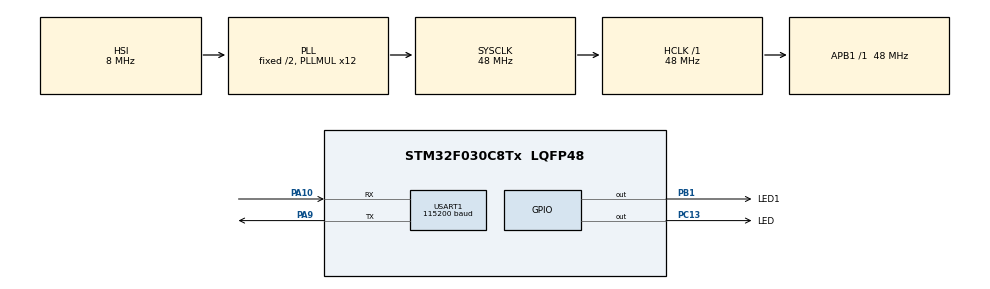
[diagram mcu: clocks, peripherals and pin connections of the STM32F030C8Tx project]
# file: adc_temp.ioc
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Mcu.Family=STM32F0
Mcu.Name=STM32F030C8Tx
Mcu.Package=LQFP48
NVIC.ADC1_IRQn=true\:0\:0\:false\:false\:true\:true\:true\:true
PA10.Mode=Asynchronous
PA10.Signal=USART1_RX
PA13.Mode=Serial_Wire
PA13.Signal=SYS_SWDIO
PA14.Mode=Serial_Wire
PA14.Signal=SYS_SWCLK
PA9.Mode=Asynchronous
PA9.Signal=USART1_TX
PB1.GPIO_Label=LED1
PB1.Signal=GPIO_Output
PC13.GPIO_Label=LED
PC13.PinState=GPIO_PIN_SET
PC13.Signal=GPIO_Output
PC14-OSC32_IN.Mode=LSE-External-Oscillator
PC14-OSC32_IN.Signal=RCC_OSC32_IN
PC15-OSC32_OUT.Mode=LSE-External-Oscillator
PC15-OSC32_OUT.Signal=RCC_OSC32_OUT
PF0-OSC_IN.Mode=HSE-External-Oscillator
PF0-OSC_IN.Signal=RCC_OSC_IN
PF1-OSC_OUT.Mode=HSE-External-Oscillator
PF1-OSC_OUT.Signal=RCC_OSC_OUT
ProjectManager.HeapSize=0x200
ProjectManager.StackSize=0x400
ProjectManager.TargetToolchain=MDK-ARM V5.32
RCC.AHBFreq_Value=48000000
RCC.APB1Freq_Value=48000000
RCC.APB1TimFreq_Value=48000000
RCC.HCLKFreq_Value=48000000
RCC.PLLMUL=RCC_PLL_MUL12
RCC.SYSCLKFreq_VALUE=48000000
RCC.SYSCLKSource=RCC_SYSCLKSOURCE_PLLCLK
USART1.BaudRate=115200
USART1.VirtualMode-Asynchronous=VM_ASYNC
VP_ADC_TempSens_Input.Mode=IN-TempSens
board=custom

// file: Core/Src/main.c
/* USER CODE BEGIN Header */
/**
  ******************************************************************************
  * @file           : main.c
  * @brief          : Main program body
  ******************************************************************************
  * @attention
  *
  * Copyright (c) 2023 STMicroelectronics.
  * All rights reserved.
  *
  * This software is licensed under terms that can be found in the LICENSE file
  * in the root directory of this software component.
  * If no LICENSE file comes with this software, it is provided AS-IS.
  *
  ******************************************************************************
  */
/* USER CODE END Header */
#include "main.h"
#include "adc.h"
#include "usart.h"
#include "gpio.h"

void SystemClock_Config(void);

int main(void)
{

  /* MCU Configuration--------------------------------------------------------*/

  /* Reset of all peripherals, Initializes the Flash interface and the Systick. */
  HAL_Init();

  /* Configure the system clock */
  SystemClock_Config();

  /* Initialize all configured peripherals */
  MX_GPIO_Init();
  MX_USART1_UART_Init();
  MX_ADC_Init();

  /* Infinite loop */
  /* USER CODE BEGIN WHILE */
  while (1)
  {
	  uint32_t v;
	float vt,temp;
	  v=0;vt=0;temp=0;
	  HAL_ADC_Start(&hadc);
	  v=HAL_ADC_GetValue(&hadc);
	  vt=v*3.3/4095;
	  temp=(1520-vt*1000)/4.6+30;
	  printf("vt=%f<----->temp=%f\r\n",vt,temp);
	  HAL_Delay(500);
    /* USER CODE END WHILE */

  }
}

void SystemClock_Config(void)
{
  RCC_OscInitTypeDef RCC_OscInitStruct = {0};
  RCC_ClkInitTypeDef RCC_ClkInitStruct = {0};
  RCC_PeriphCLKInitTypeDef PeriphClkInit = {0};

  /** Initializes the RCC Oscillators according to the specified parameters
  * in the RCC_OscInitTypeDef structure.
  */
  RCC_OscInitStruct.OscillatorType = RCC_OSCILLATORTYPE_HSI|RCC_OSCILLATORTYPE_HSI14;
  RCC_OscInitStruct.HSIState = RCC_HSI_ON;
  RCC_OscInitStruct.HSI14State = RCC_HSI14_ON;
  RCC_OscInitStruct.HSICalibrationValue = RCC_HSICALIBRATION_DEFAULT;
  RCC_OscInitStruct.HSI14CalibrationValue = 16;
  RCC_OscInitStruct.PLL.PLLState = RCC_PLL_ON;
  RCC_OscInitStruct.PLL.PLLSource = RCC_PLLSOURCE_HSI;
  RCC_OscInitStruct.PLL.PLLMUL = RCC_PLL_MUL12;
  RCC_OscInitStruct.PLL.PREDIV = RCC_PREDIV_DIV1;
  if (HAL_RCC_OscConfig(&RCC_OscInitStruct) != HAL_OK)
  {
    Error_Handler();
  }

  /** Initializes the CPU, AHB and APB buses clocks
  */
  RCC_ClkInitStruct.ClockType = RCC_CLOCKTYPE_HCLK|RCC_CLOCKTYPE_SYSCLK
                              |RCC_CLOCKTYPE_PCLK1;
  RCC_ClkInitStruct.SYSCLKSource = RCC_SYSCLKSOURCE_PLLCLK;
  RCC_ClkInitStruct.AHBCLKDivider = RCC_SYSCLK_DIV1;
  RCC_ClkInitStruct.APB1CLKDivider = RCC_HCLK_DIV1;

  if (HAL_RCC_ClockConfig(&RCC_ClkInitStruct, FLASH_LATENCY_1) != HAL_OK)
  {
    Error_Handler();
  }
  PeriphClkInit.PeriphClockSelection = RCC_PERIPHCLK_USART1;
  PeriphClkInit.Usart1ClockSelection = RCC_USART1CLKSOURCE_PCLK1;
  if (HAL_RCCEx_PeriphCLKConfig(&PeriphClkInit) != HAL_OK)
  {
    Error_Handler();
  }
}

void Error_Handler(void)
{
  __disable_irq();
  while (1)
  {
  }
}
